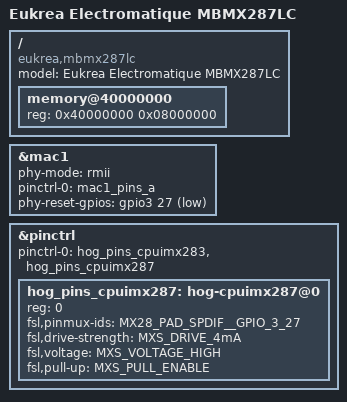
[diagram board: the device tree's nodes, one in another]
// SPDX-License-Identifier: GPL-2.0-or-later
/*
 * Copyright 2013 Eukréa Electromatique <eric@eukrea.com>
 * Copyright 2013 Eukréa Electromatique <denis@eukrea.com>
 */

/*
 * Module contains : i.MX287 + 128MB DDR2 + NAND + 2 x Ethernet PHY + RTC
 */

#include "imx28-eukrea-mbmx283lc.dts"

/ {
	model = "Eukrea Electromatique MBMX287LC";
	compatible = "eukrea,mbmx287lc", "eukrea,mbmx283lc", "eukrea,mbmx28lc", "fsl,imx28";

	memory@40000000 {
		device_type = "memory";
		reg = <0x40000000 0x08000000>;
	};
};

&mac1 {
	phy-mode = "rmii";
	pinctrl-names = "default";
	pinctrl-0 = <&mac1_pins_a>;
	phy-reset-gpios = <&gpio3 27 GPIO_ACTIVE_LOW>;
	status = "okay";
};

&pinctrl {
	pinctrl-names = "default";
	pinctrl-0 = <&hog_pins_cpuimx283 &hog_pins_cpuimx287>;
	hog_pins_cpuimx287: hog-cpuimx287@0 {
		reg = <0>;
		fsl,pinmux-ids = <
			MX28_PAD_SPDIF__GPIO_3_27
		>;
		fsl,drive-strength = <MXS_DRIVE_4mA>;
		fsl,voltage = <MXS_VOLTAGE_HIGH>;
		fsl,pull-up = <MXS_PULL_ENABLE>;
	};
};
